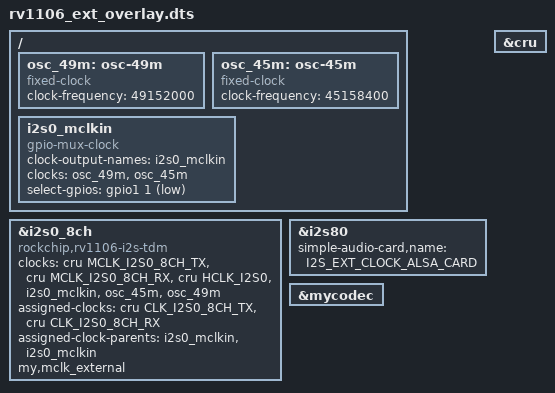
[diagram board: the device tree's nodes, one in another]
/dts-v1/;
/plugin/;

#include "rv1106.dtsi"
#include "rv1106-pinctrl.dtsi"

/ {
    fragment@0 {
        target-path = "/";

        __overlay__ {
            /******************* Активация внешних часов *******************/
            osc_49m: osc-49m {
                compatible = "fixed-clock";
                #clock-cells = <0>;
                clock-frequency = <49152000>;
            };

            osc_45m: osc-45m {
                compatible = "fixed-clock";
                #clock-cells = <0>;
                clock-frequency = <45158400>;
            };

            i2s0_mclkin: i2s0_mclkin {
                compatible = "gpio-mux-clock";
                #clock-cells = <0>;
                clock-output-names = "i2s0_mclkin";
                clocks = <&osc_49m>, <&osc_45m>;
                select-gpios = <&gpio1 1 1>;
            };
        };
    };

    fragment@1 {
        target = <&i2s0_8ch>;

        __overlay__ {
            compatible = "rockchip,rv1106-i2s-tdm";
            clocks = <&cru MCLK_I2S0_8CH_TX>, <&cru MCLK_I2S0_8CH_RX>, <&cru HCLK_I2S0>, <&i2s0_mclkin>, <&osc_45m>, <&osc_49m>;
            clock-names = "mclk_tx", "mclk_rx", "hclk", "mclk_ext", "clk_44", "clk_48";
            assigned-clocks = <&cru CLK_I2S0_8CH_TX>, <&cru CLK_I2S0_8CH_RX>;
            assigned-clock-parents = <&i2s0_mclkin>, <&i2s0_mclkin>;
            my,mclk_external;
            status = "okay";
        };
    };

    fragment@2 {
        target = <&i2s80>;

        __overlay__ {
            /delete-property/ simple-audio-card,mclk-fs;
            simple-audio-card,name = "I2S_EXT_CLOCK_ALSA_CARD";
        };
    };

    fragment@3 {
        target = <&mycodec>;

        __overlay__ {
            status = "okay";
        };
    };

    fragment@4 {
        target = <&cru>;

        __overlay__ {
            /delete-node/ assigned-clocks; // Удалить PLL-настройки, если конфликтуют
        };
    };
}
